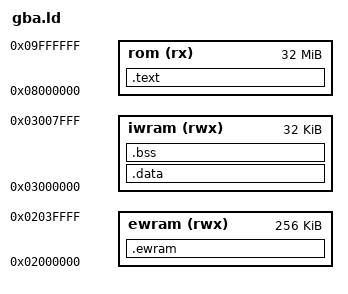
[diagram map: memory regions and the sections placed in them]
OUTPUT_FORMAT("elf32-littlearm", "elf32-bigarm", "elf32-littlearm")
OUTPUT_ARCH(arm)
ENTRY(_start)

MEMORY {
    rom   (rx)  : ORIGIN = 0x08000000, LENGTH = 32M
    iwram (rwx) : ORIGIN = 0x03000000, LENGTH = 32K
    ewram (rwx) : ORIGIN = 0x02000000, LENGTH = 256K
}

__sp_usr = 0x03007F00;
__sp_irq = 0x03007FA0;

SECTIONS {
    .text : {
        KEEP(*(.text.entry))
        *(.text .text.*)
        *(.rodata .rodata.*)
        . = ALIGN(4);
        __text_end = .;
    } > rom

    .data : AT (__text_end) {
        . = ALIGN(4);
        __data_start = .;
        *(.data .data.*)
        . = ALIGN(4);
        __data_end = .;
    } > iwram

    __data_load = LOADADDR(.data);

    .bss (NOLOAD) : {
        . = ALIGN(4);
        __bss_start = .;
        *(.bss .bss.*)
        *(COMMON)
        . = ALIGN(4);
        __bss_end = .;
    } > iwram

    .ewram (NOLOAD) : {
        . = ALIGN(4);
        __ewram_start = .;
        *(.ewram .ewram.*)
        . = ALIGN(4);
        __ewram_end = .;
    } > ewram
}
